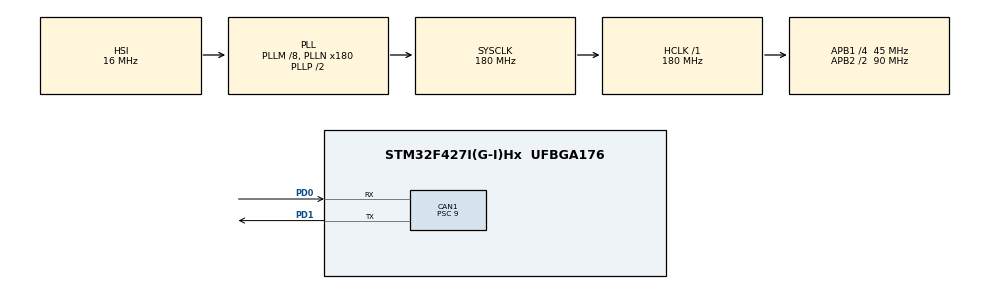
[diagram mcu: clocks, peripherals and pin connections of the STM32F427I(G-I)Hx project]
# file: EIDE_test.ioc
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CAN1.BS1=CAN_BS1_3TQ
CAN1.CalculateBaudRate=1000000
CAN1.CalculateTimeBit=1000
CAN1.CalculateTimeQuantum=200.0
CAN1.Prescaler=9
Mcu.Family=STM32F4
Mcu.Name=STM32F427I(G-I)Hx
Mcu.Package=UFBGA176
NVIC.PriorityGroup=NVIC_PRIORITYGROUP_4
PD0.Mode=CAN_Activate
PD0.Signal=CAN1_RX
PD1.Mode=CAN_Activate
PD1.Signal=CAN1_TX
ProjectManager.HeapSize=0x200
ProjectManager.StackSize=0x400
ProjectManager.TargetToolchain=Makefile
RCC.48MHZClocksFreq_Value=90000000
RCC.AHBFreq_Value=180000000
RCC.APB1CLKDivider=RCC_HCLK_DIV4
RCC.APB1Freq_Value=45000000
RCC.APB1TimFreq_Value=90000000
RCC.APB2CLKDivider=RCC_HCLK_DIV2
RCC.APB2Freq_Value=90000000
RCC.APB2TimFreq_Value=180000000
RCC.CortexFreq_Value=180000000
RCC.HCLKFreq_Value=180000000
RCC.HSE_VALUE=25000000
RCC.HSI_VALUE=16000000
RCC.LSE_VALUE=32768
RCC.PLLM=8
RCC.PLLN=180
RCC.SYSCLKFreq_VALUE=180000000
RCC.SYSCLKSource=RCC_SYSCLKSOURCE_PLLCLK
RCC.VCOOutputFreq_Value=360000000
board=custom

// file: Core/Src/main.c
/* USER CODE BEGIN Header */
/**
  ******************************************************************************
  * @file           : main.c
  * @brief          : Main program body
  ******************************************************************************
  * @attention
  *
  * Copyright (c) 2024 STMicroelectronics.
  * All rights reserved.
  *
  * This software is licensed under terms that can be found in the LICENSE file
  * in the root directory of this software component.
  * If no LICENSE file comes with this software, it is provided AS-IS.
  *
  ******************************************************************************
  */
/* USER CODE END Header */
#include "main.h"
#include "can.h"
#include "gpio.h"

void SystemClock_Config(void);

/* USER CODE BEGIN 0 */
/******全局变量定义*******/
int step        = 1;
int current_var, var_max, var_min;
int trend       = 0; // 0:increase;1:decrease
/* USER CODE END 0 */

int main(void)
{

  /* MCU Configuration--------------------------------------------------------*/

  /* Reset of all peripherals, Initializes the Flash interface and the Systick. */
  HAL_Init();

  /* Configure the system clock */
  SystemClock_Config();

  /* Initialize all configured peripherals */
  MX_GPIO_Init();
  MX_CAN1_Init();
  /* USER CODE BEGIN 2 */
  current_var = 0;
  var_max     = 40;
  var_min     = 0;

  /* USER CODE END 2 */

  /* Infinite loop */
  while (1)
  {

    /* USER CODE BEGIN 3 */
    if(current_var>=var_max)
    {
        trend = 1;
    }
    else {
        trend = 0;
    }

    if(trend==1)
        current_var++;
    else
        current_var--;
    HAL_Delay(100);
  }
  /* USER CODE END 3 */
}

void SystemClock_Config(void)
{
  RCC_OscInitTypeDef RCC_OscInitStruct = {0};
  RCC_ClkInitTypeDef RCC_ClkInitStruct = {0};

  /** Configure the main internal regulator output voltage
  */
  __HAL_RCC_PWR_CLK_ENABLE();
  __HAL_PWR_VOLTAGESCALING_CONFIG(PWR_REGULATOR_VOLTAGE_SCALE1);

  /** Initializes the RCC Oscillators according to the specified parameters
  * in the RCC_OscInitTypeDef structure.
  */
  RCC_OscInitStruct.OscillatorType = RCC_OSCILLATORTYPE_HSI;
  RCC_OscInitStruct.HSIState = RCC_HSI_ON;
  RCC_OscInitStruct.HSICalibrationValue = RCC_HSICALIBRATION_DEFAULT;
  RCC_OscInitStruct.PLL.PLLState = RCC_PLL_ON;
  RCC_OscInitStruct.PLL.PLLSource = RCC_PLLSOURCE_HSI;
  RCC_OscInitStruct.PLL.PLLM = 8;
  RCC_OscInitStruct.PLL.PLLN = 180;
  RCC_OscInitStruct.PLL.PLLP = RCC_PLLP_DIV2;
  RCC_OscInitStruct.PLL.PLLQ = 4;
  if (HAL_RCC_OscConfig(&RCC_OscInitStruct) != HAL_OK)
  {
    Error_Handler();
  }

  /** Activate the Over-Drive mode
  */
  if (HAL_PWREx_EnableOverDrive() != HAL_OK)
  {
    Error_Handler();
  }

  /** Initializes the CPU, AHB and APB buses clocks
  */
  RCC_ClkInitStruct.ClockType = RCC_CLOCKTYPE_HCLK|RCC_CLOCKTYPE_SYSCLK
                              |RCC_CLOCKTYPE_PCLK1|RCC_CLOCKTYPE_PCLK2;
  RCC_ClkInitStruct.SYSCLKSource = RCC_SYSCLKSOURCE_PLLCLK;
  RCC_ClkInitStruct.AHBCLKDivider = RCC_SYSCLK_DIV1;
  RCC_ClkInitStruct.APB1CLKDivider = RCC_HCLK_DIV4;
  RCC_ClkInitStruct.APB2CLKDivider = RCC_HCLK_DIV2;

  if (HAL_RCC_ClockConfig(&RCC_ClkInitStruct, FLASH_LATENCY_5) != HAL_OK)
  {
    Error_Handler();
  }
}

void Error_Handler(void)
{
  __disable_irq();
  while (1)
  {
  }
}
